# R7FA8M1AH register map
Vendor: Renesas; Series: RA8; File version: 1.2
CPU: CM85 r0p0, little endian, MPU, FPU, VTOR, 4 interrupt priority bits
Registers are 32-bit, read-write, reset 0x0 unless marked. A register's access mark holds for its fields unless they carry their own. Offsets are from the block's base; [hi:lo] are bit positions; {n}, {i} and the like mark numbered series; 'fields as' and 'values as' point back to an identical list.

## USBFS — USB 2.0 FS Module
Base 0x40250000
Same registers: USBFS_NS 0x50250000
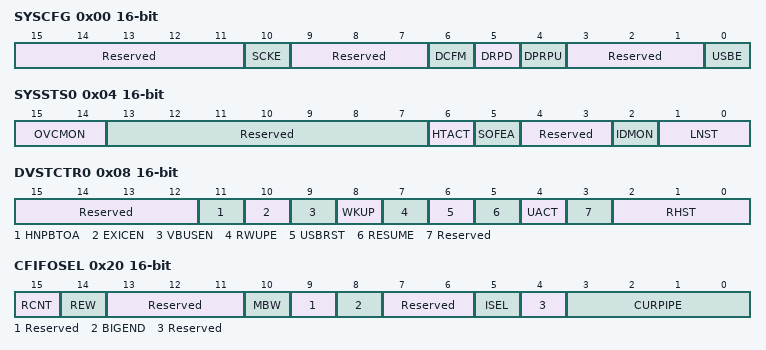
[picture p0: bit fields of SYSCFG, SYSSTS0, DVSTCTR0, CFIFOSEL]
0x00 SYSCFG 16-bit — System Configuration Control Register
  [15:11] Reserved — These bits are read as 00000. The write value should be 00000.
  [10] SCKE — USB Clock Enable
    0=Stops supplying the clock signal to the USB; 1=Enables supplying the clock signal to the USB
  [9:7] Reserved — These bits are read as 000. The write value should be 000.
  [6] DCFM — Controller Function Select
    0=Function controller is selected; 1=Host controller is selected
  [5] DRPD — D+/D- Line Resistor Control
    0=Pulling down the lines is disabled; 1=Pulling down the lines is enabled
  [4] DPRPU — D+ Line Resistor Control
    0=Pulling up the line is disabled; 1=Pulling up the line is enabled
  [3:1] Reserved — These bits are read as 000. The write value should be 000.
  [0] USBE — USB Operation Enable
    0=USB operation is disabled; 1=USB operation is enabled
0x04 SYSSTS0 16-bit ro reset not defined — System Configuration Status Register 0
  [15:14] OVCMON — External USB0_OVRCURA/ USB0_OVRCURB Input Pin MonitorThe OCVMON[1] bit indicates the status of the USBHS_OVRCURA pin. The OCVMON[0] bit indicates the status of the USBHS_OVRCURB pin.
  [13:7] Reserved — These bits are read as 0000000.
  [6] HTACT — USB Host Sequencer Status Monitor
    0=Host sequencer of the USB is completely stopped; 1=Host sequencer of the USB is not completely stopped
  [5] SOFEA — Active Monitor When the Host Controller is Selected.
    0=SOF output is stopped; 1=SOF output is operating
  [4:3] Reserved — These bits are read as 00.
  [2] IDMON — External ID0 Input Pin Monitor
    0=USB0_ID pin is low; 1=USB0_ID pin is high
  [1:0] LNST — USB Data Line Status Monitor
    0=SE0; 1=J-State; 2=K-State; 3=SE1
0x08 DVSTCTR0 16-bit — Device State Control Register 0
  [15:12] Reserved — These bits are read as 0000. The write value should be 0000.
  [11] HNPBTOA — Host Negotiation Protocol (HNP) Control This bit is used when switching from device B to device A while in OTG mode. If the HNPBTOA bit is 1, the internal function control keeps the suspended state until the HNP processing ends even though SYSCFG.DPRPU = 0 or SYSCFG.DCFM = 1 is set.
    0=Normal Operation; 1=Switching from device B to device A is enabled
  [10] EXICEN — USB0_EXICEN Output Pin Control
    0=External USB0_EXICEN pin outputs low; 1=External USB0_EXICEN pin outputs high
  [9] VBUSEN — USB0_VBUSEN Output Pin Control
    0=External USB0_VBUSEN pin outputs low; 1=External USB0_VBUSEN pin outputs high
  [8] WKUP — Wakeup Output
    0=Remote wakeup signal is not output; 1=Remote wakeup signal is output
  [7] RWUPE — Wakeup Detection Enable
    0=Downstream port wakeup is disabled; 1=Downstream port wakeup is enabled
  [6] USBRST — USB Bus Reset Output
    0=USB bus reset signal is not output; 1=USB bus reset signal is output
  [5] RESUME — Resume Output
    0=Resume signal is not output; 1=Resume signal is output
  [4] UACT — USB Bus Enable
    0=Downstream port is disabled (SOF transmission is disabled); 1=Downstream port is enabled (SOF transmission is enabled)
  [3] Reserved — This bit is read as 0. The write value should be 0.
  [2:0] RHST ro — USB Bus Reset Status
    0=Communication speed not determined; 1=Low-speed connection(When the host controller is selected) /USB bus reset in progress( When the function controller is selected); 2=Full-speed connection(When the host controller is selected) /USB bus reset in progress or full-speed connection(When the function controller is selected); 3=Setting prohibited; other=others (USB bus reset in progress(When the host controller function is selected))
0x14 CFIFO 16-bit — CFIFO Port Register
  [15:0] FIFOPORT — FIFO PortRead receive data from the FIFO buffer or write transmit data to the FIFO buffer by accessing these bits.
0x14 CFIFOL 8-bit (alternate view of CFIFO) — CFIFO Port Register L
0x15 CFIFOH 8-bit (alternate view of CFIFO) — CFIFO Port Register H
0x18 D0FIFO 16-bit — D0FIFO Port Register
  fields as CFIFO
0x18 D0FIFOL 8-bit (alternate view of D0FIFO) — D0FIFO Port Register L
0x19 D0FIFOH 8-bit (alternate view of D0FIFO) — D0FIFO Port Register H
0x1C D1FIFO 16-bit — D1FIFO Port Register
  fields as CFIFO
0x1C D1FIFOL 8-bit (alternate view of D1FIFO) — D1FIFO Port Register L
0x1D D1FIFOH 8-bit (alternate view of D1FIFO) — D1FIFO Port Register H
0x20 CFIFOSEL 16-bit — CFIFO Port Select Register
  [15] RCNT — Read Count Mode
    0=The DTLN[8:0] bits (CFIFOCRT.DTLN[8:0], D0FIFOCRT.DTLN[8:0], D1FIFOCRT.DTLN[8:0]) are cleared when all of the receive data has been read from the CFIFO.(In double buffer mode, the DTLN[8:0] bit value is cleared when all the data has been read from only a single plane.); 1=The DTLN[8:0] bits are decremented each time the receive data is read from the CFIFO
  [14] REW ro — Buffer Pointer Rewind
    0=The buffer pointer is not rewound; 1=The buffer pointer is rewound
  [13:11] Reserved — These bits are read as 000. The write value should be 000.
  [10] MBW — CFIFO Port Access Bit Width
    0=8-bit width; 1=16-bit width
  [9] Reserved — This bit is read as 0. The write value should be 0.
  [8] BIGEND — CFIFO Port Endian Control
    0=Little endian; 1=Big endian
  [7:6] Reserved — These bits are read as 00. The write value should be 00.
  [5] ISEL — CFIFO Port Access Direction When DCP is Selected
    0=Reading from the buffer memory is selected; 1=Writing to the buffer memory is selected
  [4] Reserved — This bit is read as 0. The write value should be 0.
  [3:0] CURPIPE — CFIFO Port Access Pipe Specification
    0=DCP (Default control pipe); {v}=Pipe {v} (v=1..9); other=others (Setting prohibited)
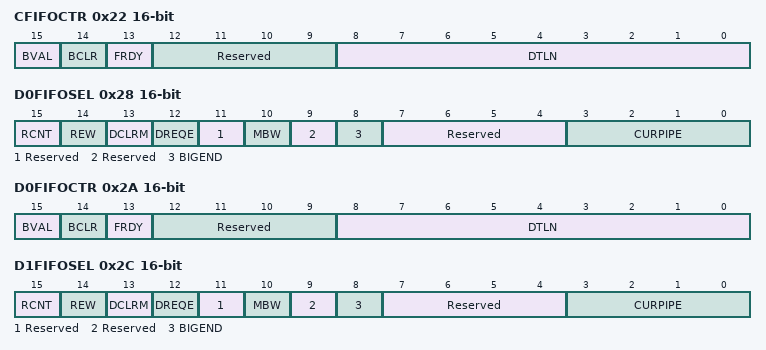
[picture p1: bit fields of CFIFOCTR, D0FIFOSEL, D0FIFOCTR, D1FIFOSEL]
0x22 CFIFOCTR 16-bit — CFIFO Port Control Register
  [15] BVAL — Buffer Memory Valid Flag
    0=Invalid; 1=Writing ended
  [14] BCLR ro — CPU Buffer Clear
    0=Invalid; 1=Clears the buffer memory on the CPU side
  [13] FRDY ro — FIFO Port Ready
    0=FIFO port access is disabled; 1=FIFO port access is enabled
  [12:9] Reserved — These bits are read as 0000. The write value should be 0000.
  [8:0] DTLN ro — Receive Data LengthIndicates the length of the receive data.
0x28 D0FIFOSEL 16-bit — D0FIFO Port Select Register
  [15] RCNT — Read Count Mode
    0=The DTLN[8:0] bits (CFIFOCRT.DTLN[8:0], D0FIFOCRT.DTLN[8:0], D1FIFOCRT.DTLN[8:0]) are cleared when all of the receive data has been read from the DnFIFO.(In double buffer mode, the DTLN bit Value is cleared when all the data has been read from only a single plane.); 1=The DTLN[8:0] bits are decremented each time the receive data is read from the DnFIFO. (n = 0, 1)
  [14] REW ro — Buffer Pointer Rewind
    values as CFIFOSEL.REW
  [13] DCLRM — Auto Buffer Memory Clear Mode Accessed after Specified Pipe Data is Read
    0=Auto buffer clear mode is disabled; 1=Auto buffer clear mode is enabled
  [12] DREQE — DMA/DTC Transfer Request Enable
    0=DMA/DTC transfer request is disabled; 1=DMA/DTC transfer request is enabled
  [11] Reserved — This bit is read as 0. The write value should be 0.
  [10] MBW — FIFO Port Access Bit Width
    0=8-bit width; 1=16-bit width
  [9] Reserved — This bit is read as 0. The write value should be 0.
  [8] BIGEND — FIFO Port Endian Control
    0=Little endian; 1=Big endian
  [7:4] Reserved — These bits are read as 0000. The write value should be 0000.
  [3:0] CURPIPE — FIFO Port Access Pipe Specification
    values as CFIFOSEL.CURPIPE
0x2A D0FIFOCTR 16-bit — D0FIFO Port Control Register
  fields as CFIFOCTR
0x2C D1FIFOSEL 16-bit — D1FIFO Port Select Register
  fields as D0FIFOSEL
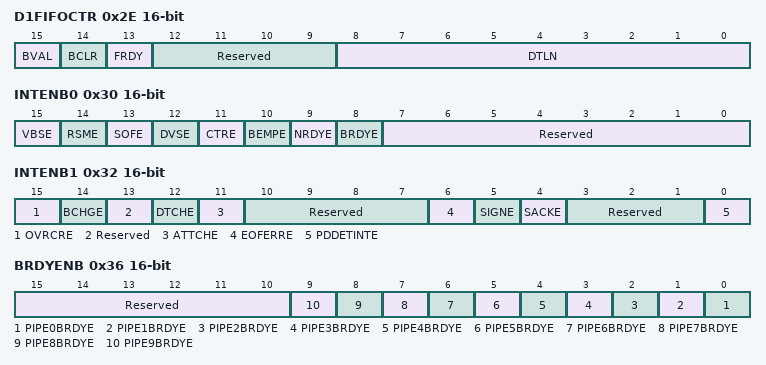
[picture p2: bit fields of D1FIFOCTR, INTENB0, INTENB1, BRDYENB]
0x2E D1FIFOCTR 16-bit — D1FIFO Port Control Register
  fields as CFIFOCTR
0x30 INTENB0 16-bit — Interrupt Enable Register 0
  [15] VBSE — VBUS Interrupt Enable
    0=Interrupt output disabled; 1=Interrupt output enabled
  [14] RSME — Resume Interrupt Enable
    0=Interrupt output disabled; 1=Interrupt output enabled
  [13] SOFE — Frame Number Update Interrupt Enable
    0=Interrupt output disabled; 1=Interrupt output enabled
  [12] DVSE — Device State Transition Interrupt Enable
    0=Interrupt output disabled; 1=Interrupt output enabled
  [11] CTRE — Control Transfer Stage Transition Interrupt Enable
    0=Interrupt output disabled; 1=Interrupt output enabled
  [10] BEMPE — Buffer Empty Interrupt Enable
    0=Interrupt output disabled; 1=Interrupt output enabled
  [9] NRDYE — Buffer Not Ready Response Interrupt Enable
    0=Interrupt output disabled; 1=Interrupt output enabled
  [8] BRDYE — Buffer Ready Interrupt Enable
    0=Interrupt output disabled; 1=Interrupt output enabled
  [7:0] Reserved — These bits are read as 00000000. The write value should be 00000000.
0x32 INTENB1 16-bit — Interrupt Enable Register 1
  [15] OVRCRE — Overcurrent Input Change Interrupt Enable
    0=Interrupt output disabled; 1=Interrupt output enabled
  [14] BCHGE — USB Bus Change Interrupt Enable
    0=Interrupt output disabled; 1=Interrupt output enabled
  [13] Reserved — This bit is read as 0. The write value should be 0.
  [12] DTCHE — Disconnection Detection Interrupt Enable
    0=Interrupt output disabled; 1=Interrupt output enabled
  [11] ATTCHE — Connection Detection Interrupt Enable
    0=Interrupt output disabled; 1=Interrupt output enabled
  [10:7] Reserved — These bits are read as 0000. The write value should be 0000.
  [6] EOFERRE — EOF Error Detection Interrupt Enable
    0=Interrupt output disabled; 1=Interrupt output enabled
  [5] SIGNE — Setup Transaction Error Interrupt Enable
    0=Interrupt output disabled; 1=Interrupt output enabled
  [4] SACKE — Setup Transaction Normal Response Interrupt Enable
    0=Interrupt output disabled; 1=Interrupt output enabled
  [3:1] Reserved — These bits are read as 000. The write value should be 000.
  [0] PDDETINTE — Port 0 Portable Device detection interrupt enabled.When PDDETINT interrupt is detected, specify disable / enable USB interrupt output.
    0=Interrupt output disabled; 1=Enable interrupt output
0x36 BRDYENB 16-bit — BRDY Interrupt Enable Register
  [15:10] Reserved — These bits are read as 000000. The write value should be 000000.
  [n] PIPE{n}BRDYE (n=0..9) — BRDY Interrupt Enable for PIPE{n}
    0=Interrupt output disabled; 1=Interrupt output enabled
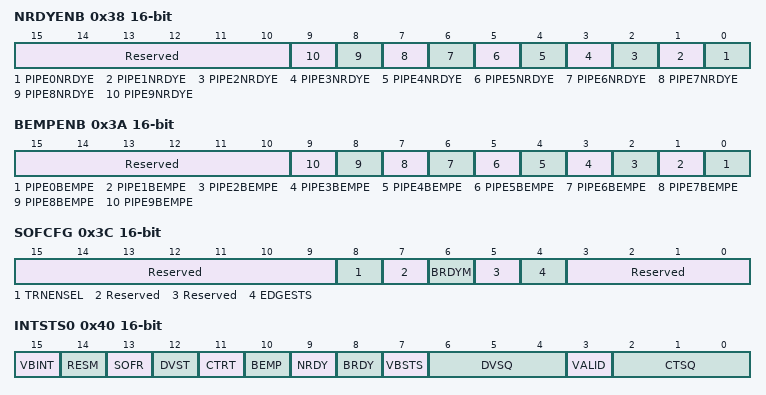
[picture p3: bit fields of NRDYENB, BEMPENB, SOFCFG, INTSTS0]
0x38 NRDYENB 16-bit — NRDY Interrupt Enable Register
  [15:10] Reserved — These bits are read as 000000. The write value should be 000000.
  [n] PIPE{n}NRDYE (n=0..9) — NRDY Interrupt Enable for PIPE{n}
    0=Interrupt output disabled; 1=Interrupt output enabled
0x3A BEMPENB 16-bit — BEMP Interrupt Enable Register
  [15:10] Reserved — These bits are read as 000000. The write value should be 000000.
  [n] PIPE{n}BEMPE (n=0..9) — BEMP Interrupt Enable for PIPE{n}
    0=Interrupt output disabled; 1=Interrupt output enabled
0x3C SOFCFG 16-bit — SOF Output Configuration Register
  [15:9] Reserved — These bits are read as 0000000. The write value should be 0000000.
  [8] TRNENSEL — Transaction-Enabled Time Select
    0=For non-low-speed communication; 1=For low-speed communication
  [7] Reserved — This bit is read as 0. The write value should be 0.
  [6] BRDYM — BRDY Interrupt Status Clear Timing
    0=Software clears the status; 1=The USB clears the status when data has been read from the FIFO buffer or data has been written to the FIFO buffer
  [5] Reserved — This bit is read as 0. The write value should be 0.
  [4] EDGESTS ro — Edge Interrupt Output Status Monitor
    0=before stopping the clock supply to the USB module; 1=the edge interrupt output signal is in the middle of the edge processing
  [3:0] Reserved — These bits are read as 0000. The write value should be 0000.
0x40 INTSTS0 16-bit (reset mask 0xFF7F) — Interrupt Status Register 0
  [15] VBINT write-0-clears read-modifies — VBUS Interrupt Status
    0=VBUS interrupts are not generated; 1=VBUS interrupts are generated
  [14] RESM write-0-clears read-modifies — Resume Interrupt Status
    0=Resume interrupts are not generated; 1=Resume interrupts are generated
  [13] SOFR write-0-clears read-modifies — Frame Number Refresh Interrupt Status
    0=SOF interrupts are not generated; 1=SOF interrupts are generated
  [12] DVST write-0-clears read-modifies — Device State Transition Interrupt Status
    0=Device state transition interrupts are not generated; 1=Device state transition interrupts are generated
  [11] CTRT write-0-clears read-modifies — Control Transfer Stage Transition Interrupt Status
    0=Control transfer stage transition interrupts are not generated; 1=Control transfer stage transition interrupts are generated
  [10] BEMP ro — Buffer Empty Interrupt Status
    0=BEMP interrupts are not generated; 1=BEMP interrupts are generated
  [9] NRDY ro — Buffer Not Ready Interrupt Status
    0=NRDY interrupts are not generated; 1=NRDY interrupts are generated
  [8] BRDY ro — Buffer Ready Interrupt Status
    0=BRDY interrupts are not generated; 1=BRDY interrupts are generated
  [7] VBSTS ro — VBUS Input Status
    0=USB0_VBUS pin is low; 1=USB0_VBUS pin is high
  [6:4] DVSQ ro — Device State
    0=Powered state; 1=Default state; 2=Address state; 3=Configured state; other=others (Suspended state)
  [3] VALID — USB Request Reception
    0=Setup packet is not received; 1=Setup packet is received
  [2:0] CTSQ ro — Control Transfer Stage
    0=Idle or setup stage; 1=Control read data stage; 2=Control read status stage; 3=Control write data stage; 4=Control write status stage; 5=Control write (no data) status stage; 6=Control transfer sequence error; other=others (Setting prohibited)
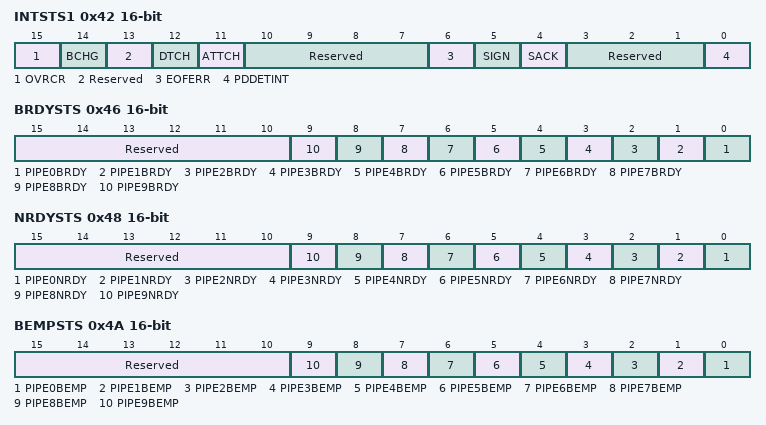
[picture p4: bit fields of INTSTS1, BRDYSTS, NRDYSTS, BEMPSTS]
0x42 INTSTS1 16-bit — Interrupt Status Register 1
  [15] OVRCR write-0-clears read-modifies — Overcurrent Input Change Interrupt Status
    0=OVRCR interrupts are not generated; 1=OVRCR interrupts are generated
  [14] BCHG write-0-clears read-modifies — USB Bus Change Interrupt Status
    0=BCHG interrupts are not generated; 1=BCHG interrupts are generated
  [13] Reserved — This bit is read as 0. The write value should be 0.
  [12] DTCH write-0-clears read-modifies — USB Disconnection Detection Interrupt Status
    0=DTCH interrupts are not generated; 1=DTCH interrupts are generated
  [11] ATTCH write-0-clears read-modifies — ATTCH Interrupt Status
    0=ATTCH interrupts are not generated; 1=ATTCH interrupts are generated
  [10:7] Reserved — These bits are read as 0000. The write value should be 0000.
  [6] EOFERR write-0-clears read-modifies — EOF Error Detection Interrupt Status
    0=EOFERR interrupts are not generated; 1=EOFERR interrupts are generated
  [5] SIGN write-0-clears read-modifies — Setup Transaction Error Interrupt Status
    0=SIGN interrupts are not generated; 1=SIGN interrupts are generated
  [4] SACK write-0-clears read-modifies — Setup Transaction Normal Response Interrupt Status
    0=SACK interrupts are not generated; 1=SACK interrupts are generated
  [3:1] Reserved — These bits are read as 000. The write value should be 000.
  [0] PDDETINT — Port 0 Portable Device Detection Interrupt Status.When the host controller function is selected, Portable Device detection interrupt status is displayed.
    0=PDDETINT interrupt not occurred; 1=PDDETINT interrupt generated
0x46 BRDYSTS 16-bit — BRDY Interrupt Status Register
  [15:10] Reserved — These bits are read as 000000. The write value should be 000000.
  [n] PIPE{n}BRDY write-0-clears read-modifies (n=0..9) — BRDY Interrupt Status for PIPE{n}
    0=Interrupts are not generated; 1=Interrupts are generated
0x48 NRDYSTS 16-bit — NRDY Interrupt Status Register
  [15:10] Reserved — These bits are read as 000000. The write value should be 000000.
  [n] PIPE{n}NRDY write-0-clears read-modifies (n=0..9) — NRDY Interrupt Status for PIPE{n}
    0=Interrupts are not generated; 1=Interrupts are generated
0x4A BEMPSTS 16-bit — BEMP Interrupt Status Register
  [15:10] Reserved — These bits are read as 000000. The write value should be 000000.
  [n] PIPE{n}BEMP write-0-clears read-modifies (n=0..9) — BEMP Interrupt Status for PIPE{n}
    0=Interrupts are not generated; 1=Interrupts are generated
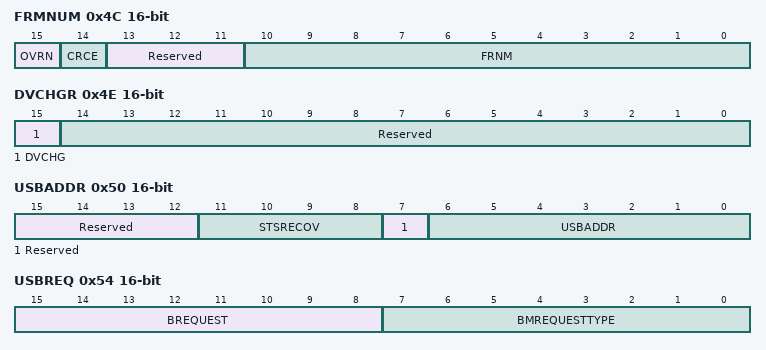
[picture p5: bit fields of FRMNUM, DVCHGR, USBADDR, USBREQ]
0x4C FRMNUM 16-bit — Frame Number Register
  [15] OVRN — Overrun/Underrun Detection Status
    0=No error; 1=An error occurred
  [14] CRCE — Receive Data Error
    0=No error; 1=An error occurred
  [13:11] Reserved — These bits are read as 000. The write value should be 000.
  [10:0] FRNM ro — Frame NumberLatest frame number
0x4E DVCHGR 16-bit — Device State Change Register
  [15] DVCHG — Device State Change
    0=Disables the writing to the USBADDR.STSRECOV[3:0] bits and USBADDR.USBADDR[6:0]; 1=Enables the writing to the USBADDR.STSRECOV[3:0] bits and USBADDR.USBADDR[6:0]
  [14:0] Reserved — These bits are read as 000000000000000. The write value should be 000000000000000.
0x50 USBADDR 16-bit — USB Address Register
  [15:12] Reserved — These bits are read as 0000. The write value should be 0000.
  [11:8] STSRECOV — Status Recovery
    4=Return to the low-speed state (bits DVSTCTR0.RHST[2:0] = 001b;(Recovery when the host controller is selected)); 8=Return to the full-speed state (bits DVSTCTR0.RHST[2:0] = 010b;(Recovery when the host controller is selected)); 9=Return to the full-speed state (bits DVSTCTR0.RHST[2:0] = 010b), bits INTSTS0.DVSQ[2:0] = 001b (Default state);(Recovery when the function controller is selected); 10=Return to the full-speed state (bits DVSTCTR0.RHST[2:0] = 010b), bits INTSTS0.DVSQ[2:0] = 010b (Address state);(Recovery when the function controller is selected); 11=Return to the full-speed state (bits DVSTCTR0.RHST[2:0] = 010b), bits INTSTS0.DVSQ[2:0] = 011b (Configured state);(Recovery when the function controller is selected); other=others (Settings other than above are prohibited.)
  [7] Reserved — This bit is read as 0. The write value should be 0.
  [6:0] USBADDR — USB AddressWhen the function controller is selected, these bits indicate the USB address assigned by the host when the SET_ADDRESS request is successfully processed.
0x54 USBREQ 16-bit — USB Request Type Register
  [15:8] BREQUEST — RequestThese bits store the USB request bRequest value.
  [7:0] BMREQUESTTYPE — Request TypeThese bits store the USB request bmRequestType value.
0x56 USBVAL 16-bit — USB Request Value Register
  [15:0] WVALUE — ValueThese bits store the USB request wValue value.
0x58 USBINDX 16-bit — USB Request Index Register
  [15:0] WINDEX — IndexThese bits store the USB request wIndex value.
0x5A USBLENG 16-bit — USB Request Length Register
  [15:0] WLENGTUH — LengthThese bits store the USB request wLength value.
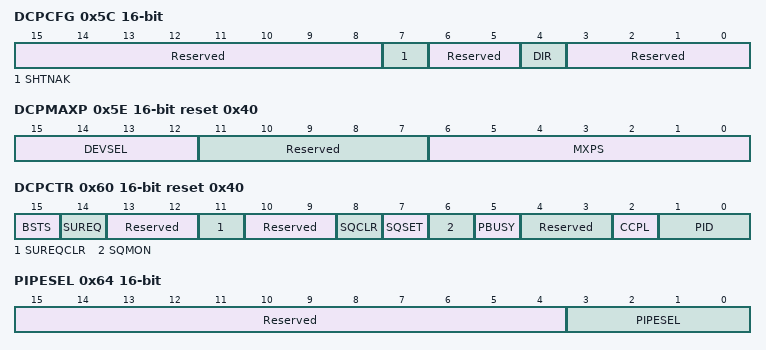
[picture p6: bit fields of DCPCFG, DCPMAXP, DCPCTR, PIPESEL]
0x5C DCPCFG 16-bit — DCP Configuration Register
  [15:8] Reserved — These bits are read as 00000000. The write value should be 00000000.
  [7] SHTNAK — Pipe Disabled at End of Transfer
    0=Pipe continued at the end of transfer; 1=Pipe disabled at the end of transfer
  [6:5] Reserved — These bits are read as 00. The write value should be 00.
  [4] DIR — Transfer Direction
    0=Data receiving direction; 1=Data transmitting direction
  [3:0] Reserved — These bits are read as 0000. The write value should be 0000.
0x5E DCPMAXP 16-bit reset 0x40 — DCP Maximum Packet Size Register
  [15:12] DEVSEL — Device Select
    0=Address 0000; 1=Address 0001; 2=Address 0010; 3=Address 0011; 4=Address 0100; 5=Address 0101; other=others (Settings prohibited.)
  [11:7] Reserved — These bits are read as 00000. The write value should be 00000.
  [6:0] MXPS — Maximum Packet SizeThese bits set the maximum amount of data (maximum packet size) in payloads for the DCP.
0x60 DCPCTR 16-bit reset 0x40 — DCP Control Register
  [15] BSTS ro — Buffer Status
    0=Buffer access is disabled; 1=Buffer access is enabled
  [14] SUREQ — Setup Token Transmission
    0=Invalid; 1=Transmits the setup packet
  [13:12] Reserved — These bits are read as 00. The write value should be 00.
  [11] SUREQCLR — SUREQ Bit Clear
    0=Invalid; 1=Clears the SUREQ bit to 0
  [10:9] Reserved — These bits are read as 00. The write value should be 00.
  [8] SQCLR — Sequence Toggle Bit Clear
    0=Invalid; 1=Specifies DATA0
  [7] SQSET — Sequence Toggle Bit Set
    0=Invalid; 1=Specifies DATA1
  [6] SQMON ro — Sequence Toggle Bit Monitor
    0=DATA0; 1=DATA1
  [5] PBUSY ro — Pipe Busy
    0=DCP is not used for the transaction; 1=DCP is used for the transaction
  [4:3] Reserved — These bits are read as 00. The write value should be 00.
  [2] CCPL — Control Transfer End Enable
    0=Invalid; 1=Completion of control transfer is enabled
  [1:0] PID — Response PID
    0=NAK response; 1=BUF response (depending on the buffer state); 2=STALL response; 3=STALL response
0x64 PIPESEL 16-bit — Pipe Window Select Register
  [15:4] Reserved — These bits are read as 000000000000. The write value should be 000000000000.
  [3:0] PIPESEL — Pipe Window Select
    0=No pipe selected; {v}=PIPE{v} (v=1..9); other=others (Settings prohibited.)
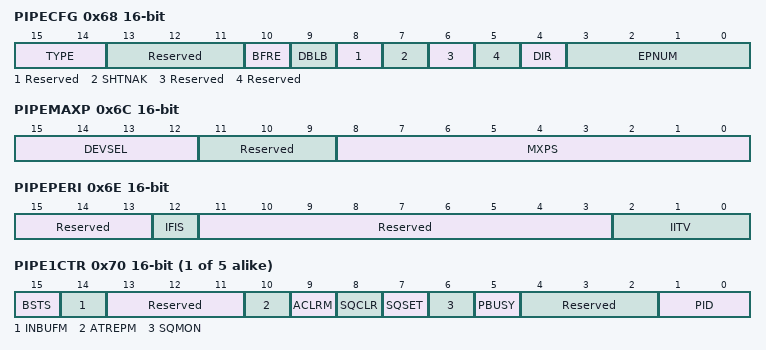
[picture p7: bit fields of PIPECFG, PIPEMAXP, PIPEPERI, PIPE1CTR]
0x68 PIPECFG 16-bit — Pipe Configuration Register
  [15:14] TYPE — Transfer Type
    0=Pipe not used; 1=Bulk transfer(PIPE1 and PIPE5) /Setting prohibited(PIPE6 to PIPE9); 2=Setting prohibited(PIPE1 and PIPE5) /Interrupt transfer(PIPE6 to PIPE9); 3=Isochronous transfer(PIPE1 and PIPE2) /Setting prohibited(PIPE3 to PIPE9)
  [13:11] Reserved — These bits are read as 000. The write value should be 000.
  [10] BFRE — BRDY Interrupt Operation Specification
    0=BRDY interrupt upon transmitting or receiving data; 1=BRDY interrupt upon completion of reading data
  [9] DBLB — Double Buffer Mode
    0=Single buffer; 1=Double buffer
  [8] Reserved — This bit is read as 0. The write value should be 0.
  [7] SHTNAK — Pipe Disabled at End of Transfer
    0=Pipe assignment continued at the end of transfer; 1=Pipe assignment disabled at the end of transfer
  [6] Reserved — This bit is read as 0. The write value should be 0.
  [5] Reserved — This bit is read as 0. The write value should be 0.
  [4] DIR — Transfer Direction
    0=Receiving direction; 1=Transmitting direction
  [3:0] EPNUM — Endpoint NumberThese bits specify the endpoint number for the selected pipe.Setting 0000b means unused pipe.
0x6C PIPEMAXP 16-bit (reset mask 0xFFBF) — Pipe Maximum Packet Size Register
  [15:12] DEVSEL — Device Select
    values as DCPMAXP.DEVSEL
  [11:9] Reserved — These bits are read as 000. The write value should be 000.
  [8:0] MXPS — Maximum Packet SizePIPE1 and PIPE2: 1 byte (001h) to 256 bytes (100h)PIPE3 to PIPE5: 8 bytes (008h), 16 bytes (010h), 32 bytes (020h), 64 bytes (040h) (Bits [8:7] and [2:0] are not provided.)PIPE6 to PIPE9: 1 byte (001h) to 64 bytes (040h) (Bits [8:7] are not provided.)
0x6E PIPEPERI 16-bit — Pipe Cycle Control Register
  [15:13] Reserved — These bits are read as 000. The write value should be 000.
  [12] IFIS — Isochronous IN Buffer Flush
    0=The buffer is not flushed; 1=The buffer is flushed
  [11:3] Reserved — These bits are read as 000000000. The write value should be 000000000.
  [2:0] IITV — Interval Error Detection IntervalSpecifies the interval error detection timing for the selected pipe in terms of frames, which is expressed as nth power of 2.
{0x6E+2i} PIPE{i}CTR (i=1..5) 16-bit — Pipe {i} Control Register
  [15] BSTS ro — Buffer Status
    0=Buffer access by the CPU is disabled; 1=Buffer access by the CPU is enabled
  [14] INBUFM ro — Transmit Buffer Monitor
    0=No data to be transmitted is in the FIFO buffer; 1=Data to be transmitted is in the FIFO buffer
  [13:11] Reserved — These bits are read as 000. The write value should be 000.
  [10] ATREPM — Auto Response Mode
    0=Auto response is disabled; 1=Auto response is enabled
  [9] ACLRM — Auto Buffer Clear Mode
    0=Disabled; 1=Enabled (all buffers are initialized)
  [8] SQCLR wo — Sequence Toggle Bit Clear
    0=Write disabled; 1=Specifies DATA0
  [7] SQSET wo — Sequence Toggle Bit Set
    0=Write disabled; 1=Specifies DATA1
  [6] SQMON ro — Sequence Toggle Bit Confirmation
    0=DATA0; 1=DATA1
  [5] PBUSY ro — Pipe Busy
    0=The relevant pipe is not used for the transaction; 1=The relevant pipe is used for the transaction
  [4:2] Reserved — These bits are read as 000. The write value should be 000.
  [1:0] PID — Response PID
    values as DCPCTR.PID
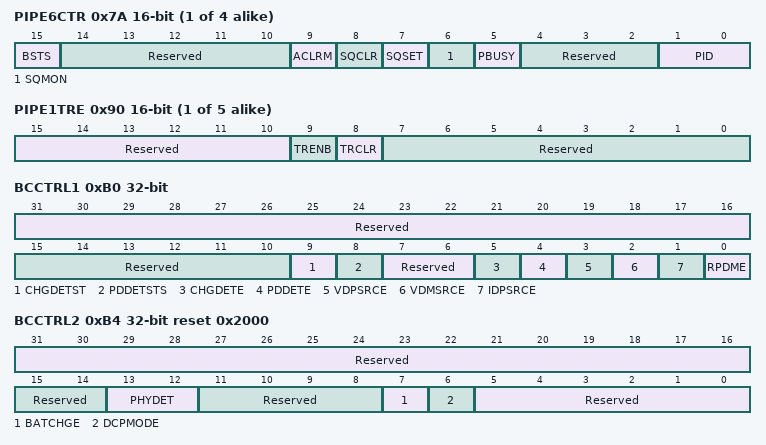
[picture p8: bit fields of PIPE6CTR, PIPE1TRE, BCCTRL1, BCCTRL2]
{0x6E+2i} PIPE{i}CTR (i=6..9) 16-bit — Pipe {i} Control Register
  [15] BSTS ro — Buffer Status
    0=Buffer access is disabled; 1=Buffer access is enabled
  [14:10] Reserved — These bits are read as 00000. The write value should be 00000.
  [9] ACLRM — Auto Buffer Clear Mode
    0=Auto buffer clear mode is disabled; 1=Auto buffer clear mode is enabled (all buffers are initialized)
  [8] SQCLR wo — Sequence Toggle Bit Clear
    0=Invalid; 1=Specifies DATA0
  [7] SQSET wo — Sequence Toggle Bit Set
    0=Invalid; 1=Specifies DATA1
  [6] SQMON ro — Sequence Toggle Bit Confirmation
    0=DATA0; 1=DATA1
  [5] PBUSY ro — Pipe Busy
    0=The relevant pipe is not used at the USB bus; 1=The relevant pipe is used at the USB bus
  [4:2] Reserved — These bits are read as 000. The write value should be 000.
  [1:0] PID — Response PID
    values as DCPCTR.PID
{0x8C+4i} PIPE{i}TRE (i=1..5) 16-bit — Pipe {i} Transaction Counter Enable Register
  [15:10] Reserved — These bits are read as 000000. The write value should be 000000.
  [9] TRENB — Transaction Counter Enable
    0=Transaction counter is disabled; 1=Transaction counter is enabled
  [8] TRCLR — Transaction Counter Clear
    0=Invalid; 1=The current counter value is cleared
  [7:0] Reserved — These bits are read as 00000000. The write value should be 00000000.
{0x8E+4i} PIPE{i}TRN (i=1..5) 16-bit — Pipe {i} Transaction Counter Register
  [15:0] TRNCNT — Transaction Counter
0xB0 BCCTRL1 — Battery Charging signal control register 1
  [31:16] Reserved — These bits are read as 0000000000000000. The write value should be 0000000000000000.
  [15:10] Reserved — These bits are read as 000000. The write value should be 000000.
  [9] CHGDETST ro — Charging Down Stream Port detection flag(Valid when CHGDETE = 1)The CHGDET input status from the USB-PHY is displayed.
    0=Not detected; 1=detection
  [8] PDDETSTS ro — Portable Device Detection Flag(Valid when UPDATE = 1)PRTBLDET input status from the USB-PHY is displayed.
    0=Not detected; 1=detection
  [7:6] Reserved — These bits are read as 00. The write value should be 00.
  [5] CHGDETE — Charging Down Stream Port detection Enable
    0=Charging Down Stream Port detection stop; 1=Charging Down Stream Port detection permission
  [4] PDDETE — Portable Device Detection Enable
    0=Portable device detection stops; 1=Portable Device detection permission
  [3] VDPSRCE — VDP_SRC, IDP_SINK enable
    0=VDP_SRC, IDP_SINK shutdown; 1=VDP_SRC, IDP_SINK output
  [2] VDMSRCE — VDM_SRC, IDM_SINK enable
    0=VDM_SRC, IDM_SINK blocking; 1=VDM_SRC, IDM_SINK output
  [1] IDPSRCE — IDP_SRC enabled
    0=IDP blocking; 1=IDP output
  [0] RPDME — UDM pulldown control.Control the pull-down resistance of the UDM terminal.
    0=Pull down OFF; 1=Pull down ON
0xB4 BCCTRL2 reset 0x2000 — Battery Charging signal control register 2
  [31:16] Reserved — These bits are read as 0000000000000000. The write value should be 0000000000000000.
  [15:14] Reserved — These bits are read as 00. The write value should be 00.
  [13:12] PHYDET — Detection sensitivity variable bit.USB-PHY Portable Device Detection, Charging D-Port Detection Sensitivity Adjust.Initial value: 10
  [11:8] Reserved — These bits are read as 0000. The write value should be 0000.
  [7] BATCHGE — Battery Charging operation enabled
    0=Battery Charging operation prohibited; 1=Battery Charging operation enabled
  [6] DCPMODE — DCP operation enableSet it to 0 when using the Peripheral Controller function.
    0=DCP operation stops; 1=DCP operation enabled
  [5:0] Reserved — These bits are read as 000000. The write value should be 000000.
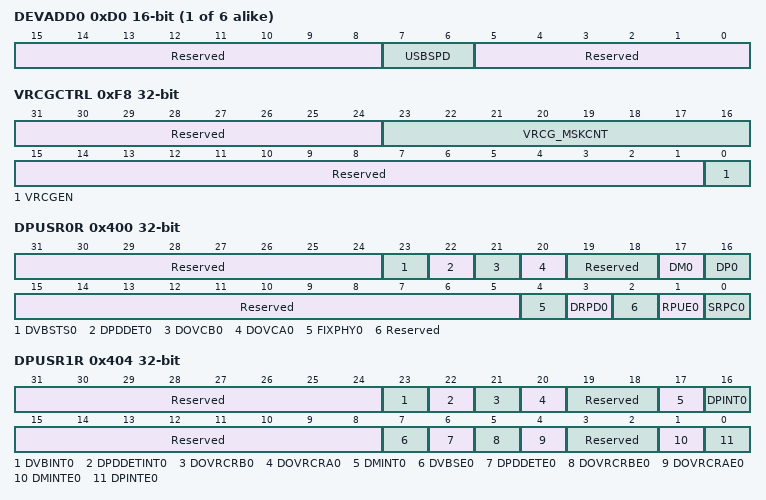
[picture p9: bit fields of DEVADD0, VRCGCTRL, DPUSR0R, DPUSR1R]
{0xD0+2i} DEVADD{i} (i=0..5) 16-bit — Device Address {i} Configuration Register
  [15:8] Reserved — These bits are read as 00000000. The write value should be 00000000.
  [7:6] USBSPD — Transfer Speed of Communication Target Device
    0=DEVADDn is not used; 1=Low speed; 2=Full speed; 3=Setting prohibited
  [5:0] Reserved — These bits are read as 000000. The write value should be 000000.
0xF8 VRCGCTRL — VRCORE clock gating set register
  [31:24] Reserved — These bits are read as 00000000. The write value should be 00000000.
  [23:16] VRCG_MSKCNT — VRCORE clock gating mask count
  [15:1] Reserved — These bits are read as 000000000000000. The write value should be 000000000000000.
  [0] VRCGEN — VRCORE clock gating enable
    0=diable; 1=enable
0x400 DPUSR0R (reset mask 0xFF4CFFFF) — Deep Software Standby USB Transceiver Control/Pin Monitor Register
  [31:24] Reserved — These bits are read as 00000000. The write value should be 00000000.
  [23] DVBSTS0 ro — USB VBUS InputIndicates the VBUS input signal of the USB.
  [22] DPDDET0 ro — USB 0 PRTBLDET input
  [21] DOVCB0 ro — USB OVRCURB InputIndicates the OVRCURB input signal of the USB.
  [20] DOVCA0 ro — USB OVRCURA InputIndicates the OVRCURA input signal of the USB.
  [19:18] Reserved — These bits are read as 00. The write value should be 00.
  [17] DM0 ro — USB D-InputIndicates the D- input signal of the USB.
  [16] DP0 ro — USB0 D+ InputIndicates the D+ input signal of the USB.
  [15:5] Reserved — These bits are read as 00000000000. The write value should be 00000000000.
  [4] FIXPHY0 — USB Transceiver Output Fix
    0=The outputs are fixed in normal mode and on return from deep software standby mode; 1=The outputs are fixed on transitions to deep software standby mode
  [3] DRPD0 — D+/D- Pull-Down Resistor Control
    0=Disables DP/DM pull-down resistor; 1=Enables DP/DM pull-down resistor
  [2] Reserved — This bit is read as 0. The write value should be 0.
  [1] RPUE0 — DP Pull-Up Resistor Control
    0=Disables DP pull-up resistor; 1=Enables DP pull-up resistor
  [0] SRPC0 — USB Single End Receiver Control
    0=Input through the DP and DM inputs is disabled; 1=Input through the DP and DM inputs is enabled
0x404 DPUSR1R — Deep Software Standby USB Suspend/Resume Interrupt Register
  [31:24] Reserved — These bits are read as 00000000. The write value should be 00000000.
  [23] DVBINT0 ro — USB VBUS Interrupt Source Recovery
    0=The system has not returned from deep software standby mode; 1=The system has returned from deep software standby mode
  [22] DPDDETINT0 ro — USB PDDET Interrupt Source Recovery
    values as DVBINT0
  [21] DOVRCRB0 ro — USB OVRCURB Interrupt Source Recovery
    values as DVBINT0
  [20] DOVRCRA0 ro — USB OVRCURA Interrupt Source Recovery
    values as DVBINT0
  [19:18] Reserved — These bits are read as 00. The write value should be 00.
  [17] DMINT0 ro — USB DM Interrupt Source Recovery
    values as DVBINT0
  [16] DPINT0 ro — USB DP Interrupt Source Recovery
    values as DVBINT0
  [15:8] Reserved — These bits are read as 00000000. The write value should be 00000000.
  [7] DVBSE0 — USB VBUS Interrupt Enable/Clear
    0=Recovery from deep software standby mode is disabled; 1=Recovery from deep software standby mode is enabled
  [6] DPDDETE0 — USB PDDET Interrupt Enable/Clear
    values as DVBSE0
  [5] DOVRCRBE0 — USB OVRCURB Interrupt Enable/Clear
    values as DVBSE0
  [4] DOVRCRAE0 — USB OVRCURA Interrupt Enable/Clear
    values as DVBSE0
  [3:2] Reserved — These bits are read as 00. The write value should be 00.
  [1] DMINTE0 — USB DM Interrupt Enable/Clear
    values as DVBSE0
  [0] DPINTE0 — USB DP Interrupt Enable/Clear
    values as DVBSE0
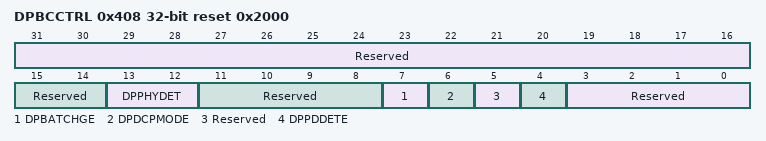
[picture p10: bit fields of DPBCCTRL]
0x408 DPBCCTRL reset 0x2000 — Deep standby USB Battery Charging function register
  [31:16] Reserved — These bits are read as 0000000000000000. The write value should be 0000000000000000.
  [15:14] Reserved — These bits are read as 00. The write value should be 00.
  [13:12] DPPHYDET — Detection sensitivity variable bit.USB-PHY Portable Device Detection, Charging D-Port Detection Sensitivity Adjust.Initial value: 10
  [11:8] Reserved — These bits are read as 0000. The write value should be 0000.
  [7] DPBATCHGE — USBattery Charging operation enabled
    values as BCCTRL2.BATCHGE
  [6] DPDCPMODE — DCP operation enable.Set it to 0 when using the Peripheral Controller function.
    0=DCP operation stops; 1=DCP operation enabled
  [5] Reserved — This bit is read as 0. The write value should be 0.
  [4] DPPDDETE — Portable Device Detection Enable
    values as BCCTRL1.PDDETE
  [3:0] Reserved — These bits are read as 0000. The write value should be 0000.
